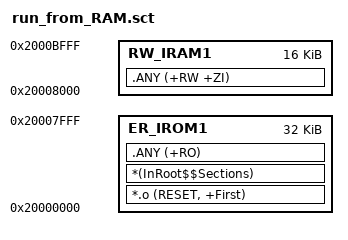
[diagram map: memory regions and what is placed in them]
; *************************************************************
; *** Scatter-Loading Description File generated by uVision ***
; *************************************************************

;R_ROM1 0x01000000 0x40000 	  		
;{
	;ER_ROM1 0x01000000 0x40000  	    
	;{
   		;*.o (RESET, +First)
   		;*(InRoot$$Sections)
  		;* (+RO)
  	;}
    
    ;ARM_LIB_STACK 0x20009000 EMPTY -0x1000 
  	;{
    
  	;}
    
    ;RW_RAM 0x20009000 0x3000         ;6K RW ZI           
	;{
		;*(ram_code)
  		;* (+RW +ZI)
		
  	;}
    
;}

LR_IROM1 0x20000000 0x00008000  {    ; load region size_region
  ER_IROM1 0x20000000 0x00008000  {  ; load address = execution address
   *.o (RESET, +First)
   *(InRoot$$Sections)
   .ANY (+RO)
  }
  RW_IRAM1 0x20008000 0x00004000  {  ; RW data
   .ANY (+RW +ZI)
  }
}
